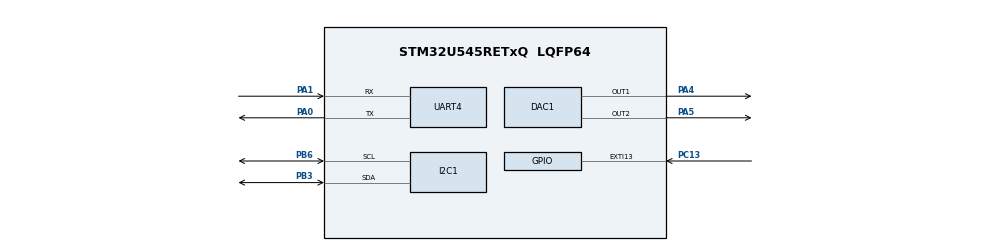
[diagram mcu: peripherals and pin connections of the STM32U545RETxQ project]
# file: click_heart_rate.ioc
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CORTEX_M33_NS.userName=CORTEX_M33
DAC1.DAC_Channel-DAC_OUT1=DAC_CHANNEL_1
DAC1.DAC_Channel-DAC_OUT2=DAC_CHANNEL_2
DAC1.DAC_HighFrequency=DAC_HIGH_FREQUENCY_INTERFACE_MODE_AUTOMATIC
DAC1.DAC_OutputBuffer_OUT1-DAC_OUT1=DAC_OUTPUTBUFFER_ENABLE
DAC1.DAC_OutputBuffer_OUT2-DAC_OUT2=DAC_OUTPUTBUFFER_ENABLE
DAC1.DAC_SignedFormat-DAC_OUT1=DISABLE
I2C1.Timing=0x00000E14
Mcu.Family=STM32U5
Mcu.Name=STM32U545RETxQ
Mcu.Package=LQFP64
NUCLEO-U545RE-Q.BUTTON=1
NUCLEO-U545RE-Q.LD2=true
NUCLEO-U545RE-Q.VCP=true
NVIC.EXTI13_IRQn=true\:0\:0\:false\:false\:true\:false\:true\:true
NVIC.PriorityGroup=NVIC_PRIORITYGROUP_4
PA0.Mode=Asynchronous
PA0.Signal=UART4_TX
PA1.Mode=Asynchronous
PA1.Signal=UART4_RX
PA4.Signal=COMP_DAC11_group
PA5.Signal=COMP_DAC12_group
PB3\ (JTDO/TRACESWO).Mode=I2C
PB3\ (JTDO/TRACESWO).Signal=I2C1_SDA
PB6.Mode=I2C
PB6.Signal=I2C1_SCL
PC13.Signal=GPXTI13
PWR.PowerMode=PWR_SMPS_SUPPLY
ProjectManager.HeapSize=0x200
ProjectManager.StackSize=0x400
ProjectManager.TargetToolchain=STM32CubeIDE
RCC.ADCFreq_Value=16000000
RCC.DACCLockSelectionVirtual=RCC_DAC1CLKSOURCE_LSI
RCC.DACCLockSelectionVirtualString=RCC_DAC1CLKSOURCE_LSI
RCC.EPOD_VALUE=4000000
RCC.HSE_VALUE=16000000
RCC.HSI48_VALUE=48000000
RCC.HSI_VALUE=16000000
RCC.LSE_VALUE=32768
RCC.LSIDIV_VALUE=32000
RCC.MSI_VALUE=4000000
RCC.USBFreq_Value=48000000
RCC.VCOOutputFreq_Value=516000000
SH.COMP_DAC11_group.0=DAC1_OUT1,DAC_OUT1
SH.COMP_DAC12_group.0=DAC1_OUT2,DAC_OUT2
VP_ICACHE_VS_ICACHE.Mode=DirectMappedCache
VP_LPBAMQUEUE_VS_QUEUE.Mode=QUEUEMODE
VP_LPBAM_VS_SIG1.Mode=SmartRun
VP_LPBAM_VS_SIG4.Mode=LPDMA1
VP_MEMORYMAP_VS_MEMORYMAP.Mode=CurAppReg
VP_NUCLEO-U545RE-Q_VS_BSP_COMMON.Mode=COMMON
VP_PWR_VS_LPOM.Mode=PowerOptimisation
VP_PWR_VS_SECSignals.Mode=Security/Privilege
board=NUCLEO-U545RE-Q

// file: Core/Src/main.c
 /* USER CODE BEGIN Header */
/**
 ******************************************************************************
 * @file           : main.c
 * @brief          : Main program body
 ******************************************************************************
 * @attention
 *
 * Copyright (c) 2024 STMicroelectronics.
 * All rights reserved.
 *
 * This software is licensed under terms that can be found in the LICENSE file
 * in the root directory of this software component.
 * If no LICENSE file comes with this software, it is provided AS-IS.
 *
 ******************************************************************************
 */
/* USER CODE END Header */
#include "main.h"
//test
//test ismail

COM_InitTypeDef BspCOMInit;

DAC_HandleTypeDef hdac1;

I2C_HandleTypeDef hi2c1;

UART_HandleTypeDef huart4;

void SystemClock_Config(void);
static void SystemPower_Config(void);
static void MX_GPIO_Init(void);
static void MX_ICACHE_Init(void);
static void MX_I2C1_Init(void);
static void MX_UART4_Init(void);
static void MX_DAC1_Init(void);

/* USER CODE BEGIN 0 */

/*

/* USER CODE END 0 */

int main(void)
{

  /* MCU Configuration--------------------------------------------------------*/

  /* Reset of all peripherals, Initializes the Flash interface and the Systick. */
  HAL_Init();

  /* Configure the system clock */
  SystemClock_Config();

  /* Configure the System Power */
  SystemPower_Config();

  /* Initialize all configured peripherals */
  MX_GPIO_Init();
  MX_ICACHE_Init();
  MX_I2C1_Init();
  MX_UART4_Init();
  MX_DAC1_Init();
  /* USER CODE BEGIN 2 */
  HAL_DAC_Start(&hdac1, DAC_CHANNEL_1);
  HAL_DAC_Start(&hdac1, DAC_CHANNEL_2);

  AE_Max30100Init(&hi2c1);
  /* USER CODE END 2 */

  /* Initialize led */
  BSP_LED_Init(LED_GREEN);

  /* Initialize USER push-button, will be used to trigger an interrupt each time it's pressed.*/
  BSP_PB_Init(BUTTON_USER, BUTTON_MODE_EXTI);

  /* Initialize COM1 port (115200, 8 bits (7-bit data + 1 stop bit), no parity */
  BspCOMInit.BaudRate   = 115200;
  BspCOMInit.WordLength = COM_WORDLENGTH_8B;
  BspCOMInit.StopBits   = COM_STOPBITS_1;
  BspCOMInit.Parity     = COM_PARITY_NONE;
  BspCOMInit.HwFlowCtl  = COM_HWCONTROL_NONE;
  if (BSP_COM_Init(COM1, &BspCOMInit) != BSP_ERROR_NONE)
  {
    Error_Handler();
  }

  /* Infinite loop */
  /* USER CODE BEGIN WHILE */

	while (1) {
		getHR(&hi2c1);
	}
    /* USER CODE END WHILE */

}

void SystemClock_Config(void)
{
  RCC_OscInitTypeDef RCC_OscInitStruct = {0};
  RCC_ClkInitTypeDef RCC_ClkInitStruct = {0};

  /** Configure the main internal regulator output voltage
  */
  if (HAL_PWREx_ControlVoltageScaling(PWR_REGULATOR_VOLTAGE_SCALE4) != HAL_OK)
  {
    Error_Handler();
  }

  /** Initializes the CPU, AHB and APB buses clocks
  */
  RCC_OscInitStruct.OscillatorType = RCC_OSCILLATORTYPE_HSI|RCC_OSCILLATORTYPE_LSI
                              |RCC_OSCILLATORTYPE_MSI;
  RCC_OscInitStruct.HSIState = RCC_HSI_ON;
  RCC_OscInitStruct.HSICalibrationValue = RCC_HSICALIBRATION_DEFAULT;
  RCC_OscInitStruct.LSIState = RCC_LSI_ON;
  RCC_OscInitStruct.MSIState = RCC_MSI_ON;
  RCC_OscInitStruct.MSICalibrationValue = RCC_MSICALIBRATION_DEFAULT;
  RCC_OscInitStruct.MSIClockRange = RCC_MSIRANGE_4;
  RCC_OscInitStruct.LSIDiv = RCC_LSI_DIV1;
  RCC_OscInitStruct.PLL.PLLState = RCC_PLL_NONE;
  if (HAL_RCC_OscConfig(&RCC_OscInitStruct) != HAL_OK)
  {
    Error_Handler();
  }

  /** Initializes the CPU, AHB and APB buses clocks
  */
  RCC_ClkInitStruct.ClockType = RCC_CLOCKTYPE_HCLK|RCC_CLOCKTYPE_SYSCLK
                              |RCC_CLOCKTYPE_PCLK1|RCC_CLOCKTYPE_PCLK2
                              |RCC_CLOCKTYPE_PCLK3;
  RCC_ClkInitStruct.SYSCLKSource = RCC_SYSCLKSOURCE_MSI;
  RCC_ClkInitStruct.AHBCLKDivider = RCC_SYSCLK_DIV1;
  RCC_ClkInitStruct.APB1CLKDivider = RCC_HCLK_DIV1;
  RCC_ClkInitStruct.APB2CLKDivider = RCC_HCLK_DIV1;
  RCC_ClkInitStruct.APB3CLKDivider = RCC_HCLK_DIV1;

  if (HAL_RCC_ClockConfig(&RCC_ClkInitStruct, FLASH_LATENCY_0) != HAL_OK)
  {
    Error_Handler();
  }
}

/**
  * @brief Power Configuration
  * @retval None
  */
static void SystemPower_Config(void)
{

  /*
   * Switch to SMPS regulator instead of LDO
   */
  if (HAL_PWREx_ConfigSupply(PWR_SMPS_SUPPLY) != HAL_OK)
  {
    Error_Handler();
  }
}

static void MX_DAC1_Init(void)
{

  DAC_ChannelConfTypeDef sConfig = {0};
  DAC_AutonomousModeConfTypeDef sAutonomousMode = {0};

  /** DAC Initialization
  */
  hdac1.Instance = DAC1;
  if (HAL_DAC_Init(&hdac1) != HAL_OK)
  {
    Error_Handler();
  }

  /** DAC channel OUT1 config
  */
  sConfig.DAC_HighFrequency = DAC_HIGH_FREQUENCY_INTERFACE_MODE_AUTOMATIC;
  sConfig.DAC_DMADoubleDataMode = DISABLE;
  sConfig.DAC_SignedFormat = DISABLE;
  sConfig.DAC_SampleAndHold = DAC_SAMPLEANDHOLD_DISABLE;
  sConfig.DAC_Trigger = DAC_TRIGGER_NONE;
  sConfig.DAC_OutputBuffer = DAC_OUTPUTBUFFER_ENABLE;
  sConfig.DAC_ConnectOnChipPeripheral = DAC_CHIPCONNECT_EXTERNAL;
  sConfig.DAC_UserTrimming = DAC_TRIMMING_FACTORY;
  if (HAL_DAC_ConfigChannel(&hdac1, &sConfig, DAC_CHANNEL_1) != HAL_OK)
  {
    Error_Handler();
  }

  /** Configure Autonomous Mode
  */
  sAutonomousMode.AutonomousModeState = DAC_AUTONOMOUS_MODE_DISABLE;
  if (HAL_DACEx_SetConfigAutonomousMode(&hdac1, &sAutonomousMode) != HAL_OK)
  {
    Error_Handler();
  }

  /** DAC channel OUT2 config
  */
  if (HAL_DAC_ConfigChannel(&hdac1, &sConfig, DAC_CHANNEL_2) != HAL_OK)
  {
    Error_Handler();
  }

}

static void MX_I2C1_Init(void)
{

  hi2c1.Instance = I2C1;
  hi2c1.Init.Timing = 0x00000E14;
  hi2c1.Init.OwnAddress1 = 0;
  hi2c1.Init.AddressingMode = I2C_ADDRESSINGMODE_7BIT;
  hi2c1.Init.DualAddressMode = I2C_DUALADDRESS_DISABLE;
  hi2c1.Init.OwnAddress2 = 0;
  hi2c1.Init.OwnAddress2Masks = I2C_OA2_NOMASK;
  hi2c1.Init.GeneralCallMode = I2C_GENERALCALL_DISABLE;
  hi2c1.Init.NoStretchMode = I2C_NOSTRETCH_DISABLE;
  if (HAL_I2C_Init(&hi2c1) != HAL_OK)
  {
    Error_Handler();
  }

  /** Configure Analogue filter
  */
  if (HAL_I2CEx_ConfigAnalogFilter(&hi2c1, I2C_ANALOGFILTER_ENABLE) != HAL_OK)
  {
    Error_Handler();
  }

  /** Configure Digital filter
  */
  if (HAL_I2CEx_ConfigDigitalFilter(&hi2c1, 0) != HAL_OK)
  {
    Error_Handler();
  }

}

static void MX_ICACHE_Init(void)
{

  /** Enable instruction cache in 1-way (direct mapped cache)
  */
  if (HAL_ICACHE_ConfigAssociativityMode(ICACHE_1WAY) != HAL_OK)
  {
    Error_Handler();
  }
  if (HAL_ICACHE_Enable() != HAL_OK)
  {
    Error_Handler();
  }

}

static void MX_UART4_Init(void)
{

  huart4.Instance = UART4;
  huart4.Init.BaudRate = 115200;
  huart4.Init.WordLength = UART_WORDLENGTH_8B;
  huart4.Init.StopBits = UART_STOPBITS_1;
  huart4.Init.Parity = UART_PARITY_NONE;
  huart4.Init.Mode = UART_MODE_TX_RX;
  huart4.Init.HwFlowCtl = UART_HWCONTROL_NONE;
  huart4.Init.OverSampling = UART_OVERSAMPLING_16;
  huart4.Init.OneBitSampling = UART_ONE_BIT_SAMPLE_DISABLE;
  huart4.Init.ClockPrescaler = UART_PRESCALER_DIV1;
  huart4.AdvancedInit.AdvFeatureInit = UART_ADVFEATURE_NO_INIT;
  if (HAL_UART_Init(&huart4) != HAL_OK)
  {
    Error_Handler();
  }
  if (HAL_UARTEx_SetTxFifoThreshold(&huart4, UART_TXFIFO_THRESHOLD_1_8) != HAL_OK)
  {
    Error_Handler();
  }
  if (HAL_UARTEx_SetRxFifoThreshold(&huart4, UART_RXFIFO_THRESHOLD_1_8) != HAL_OK)
  {
    Error_Handler();
  }
  if (HAL_UARTEx_DisableFifoMode(&huart4) != HAL_OK)
  {
    Error_Handler();
  }

}

static void MX_GPIO_Init(void)
{

  /* GPIO Ports Clock Enable */
  __HAL_RCC_GPIOA_CLK_ENABLE();
  __HAL_RCC_GPIOB_CLK_ENABLE();

}

void Error_Handler(void)
{
	__disable_irq();
	while (1) {
	}
}
